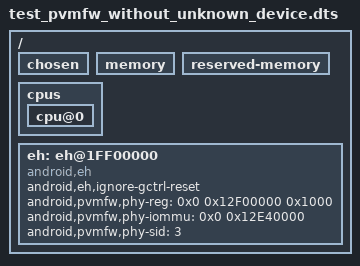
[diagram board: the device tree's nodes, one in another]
/dts-v1/;
/plugin/;

/ {
    chosen {
    };

    memory {
    };

    reserved-memory {
    };

    cpus {
        cpu@0 {
        };
    };

    eh: eh@1FF00000 {
        compatible = "android,eh";
        android,eh,ignore-gctrl-reset;
        android,pvmfw,phy-reg = <0x0 0x12F00000 0x1000>;
        android,pvmfw,phy-iommu = <0x0 0x12E40000>;
        android,pvmfw,phy-sid = <3>;
    };
};
